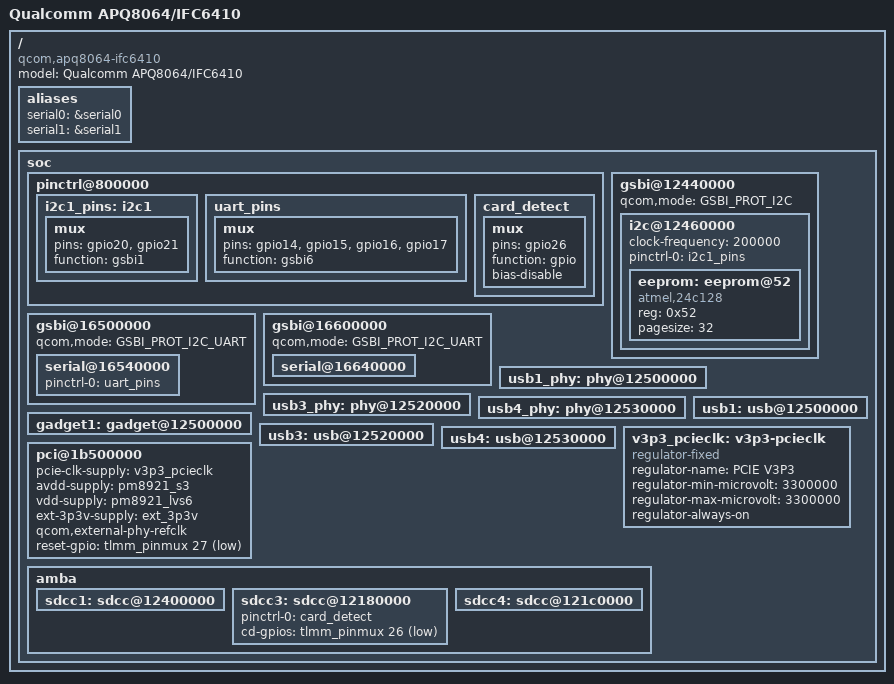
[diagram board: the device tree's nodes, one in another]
#include "qcom-apq8064-v2.0.dtsi"
#include <dt-bindings/gpio/gpio.h>

/ {
	model = "Qualcomm APQ8064/IFC6410";
	compatible = "qcom,apq8064-ifc6410", "qcom,apq8064";

	aliases {
		serial0 = &serial0;
		serial1 = &serial1;
	};

	soc {
		pinctrl@800000 {
			i2c1_pins: i2c1 {
				mux {
					pins = "gpio20", "gpio21";
					function = "gsbi1";
				};
			};

			uart_pins: uart_pins {
				mux {
					pins = "gpio14", "gpio15", "gpio16", "gpio17";
					function = "gsbi6";
				};
			};

			card_detect: card_detect {
				mux {
					pins = "gpio26";
					function = "gpio";
					bias-disable;
				};
			};
		};

		gsbi@12440000 {
			status = "okay";
			qcom,mode = <GSBI_PROT_I2C>;

			i2c@12460000 {
				status = "okay";
				clock-frequency = <200000>;
				pinctrl-0 = <&i2c1_pins>;
				pinctrl-names = "default";

				eeprom: eeprom@52 {
					compatible = "atmel,24c128";
					reg = <0x52>;
					pagesize = <32>;
				};
			};
		};

		gsbi@16500000 {
			status = "ok";
			qcom,mode = <GSBI_PROT_I2C_UART>;

			serial@16540000 {
				status = "ok";

				pinctrl-names = "default";
				pinctrl-0 = <&uart_pins>;
			};
		};

		gsbi@16600000 {
			status = "ok";
			qcom,mode = <GSBI_PROT_I2C_UART>;
			serial@16640000 {
				status = "ok";
			};
		};

		/* OTG */
		usb1_phy:phy@12500000 {
			status = "ok";
		};

		usb3_phy:phy@12520000 {
			status = "ok";
		};

		usb4_phy:phy@12530000 {
			status = "ok";
		};

		gadget1:gadget@12500000 {
			status = "ok";
		};

		/* OTG */
		usb1: usb@12500000 {
			status = "ok";
		};

		usb3: usb@12520000 {
			status = "ok";
		};

		usb4: usb@12530000 {
			status = "ok";
		};
		
		/* on board fixed 3.3v supply */
		v3p3_pcieclk: v3p3-pcieclk {
			compatible = "regulator-fixed";
			regulator-name = "PCIE V3P3";
			regulator-min-microvolt = <3300000>;
			regulator-max-microvolt = <3300000>;
			regulator-always-on;
		};

		pci@1b500000 {
			status = "ok";
			pcie-clk-supply	= <&v3p3_pcieclk>;
			avdd-supply	= <&pm8921_s3>;
			vdd-supply	= <&pm8921_lvs6>;
			ext-3p3v-supply = <&ext_3p3v>;
			qcom,external-phy-refclk;
			reset-gpio = <&tlmm_pinmux 27 GPIO_ACTIVE_LOW>;
		};

		amba {
			/* eMMC */
			sdcc1: sdcc@12400000 {
				status = "okay";
			};

			/* External micro SD card */
			sdcc3: sdcc@12180000 {
				status = "okay";
				pinctrl-names	= "default";
				pinctrl-0	= <&card_detect>;
				cd-gpios	= <&tlmm_pinmux 26 GPIO_ACTIVE_LOW>;
			};
			/* WLAN */
			sdcc4: sdcc@121c0000 {
				status = "okay";
			};
		};
	};
};
